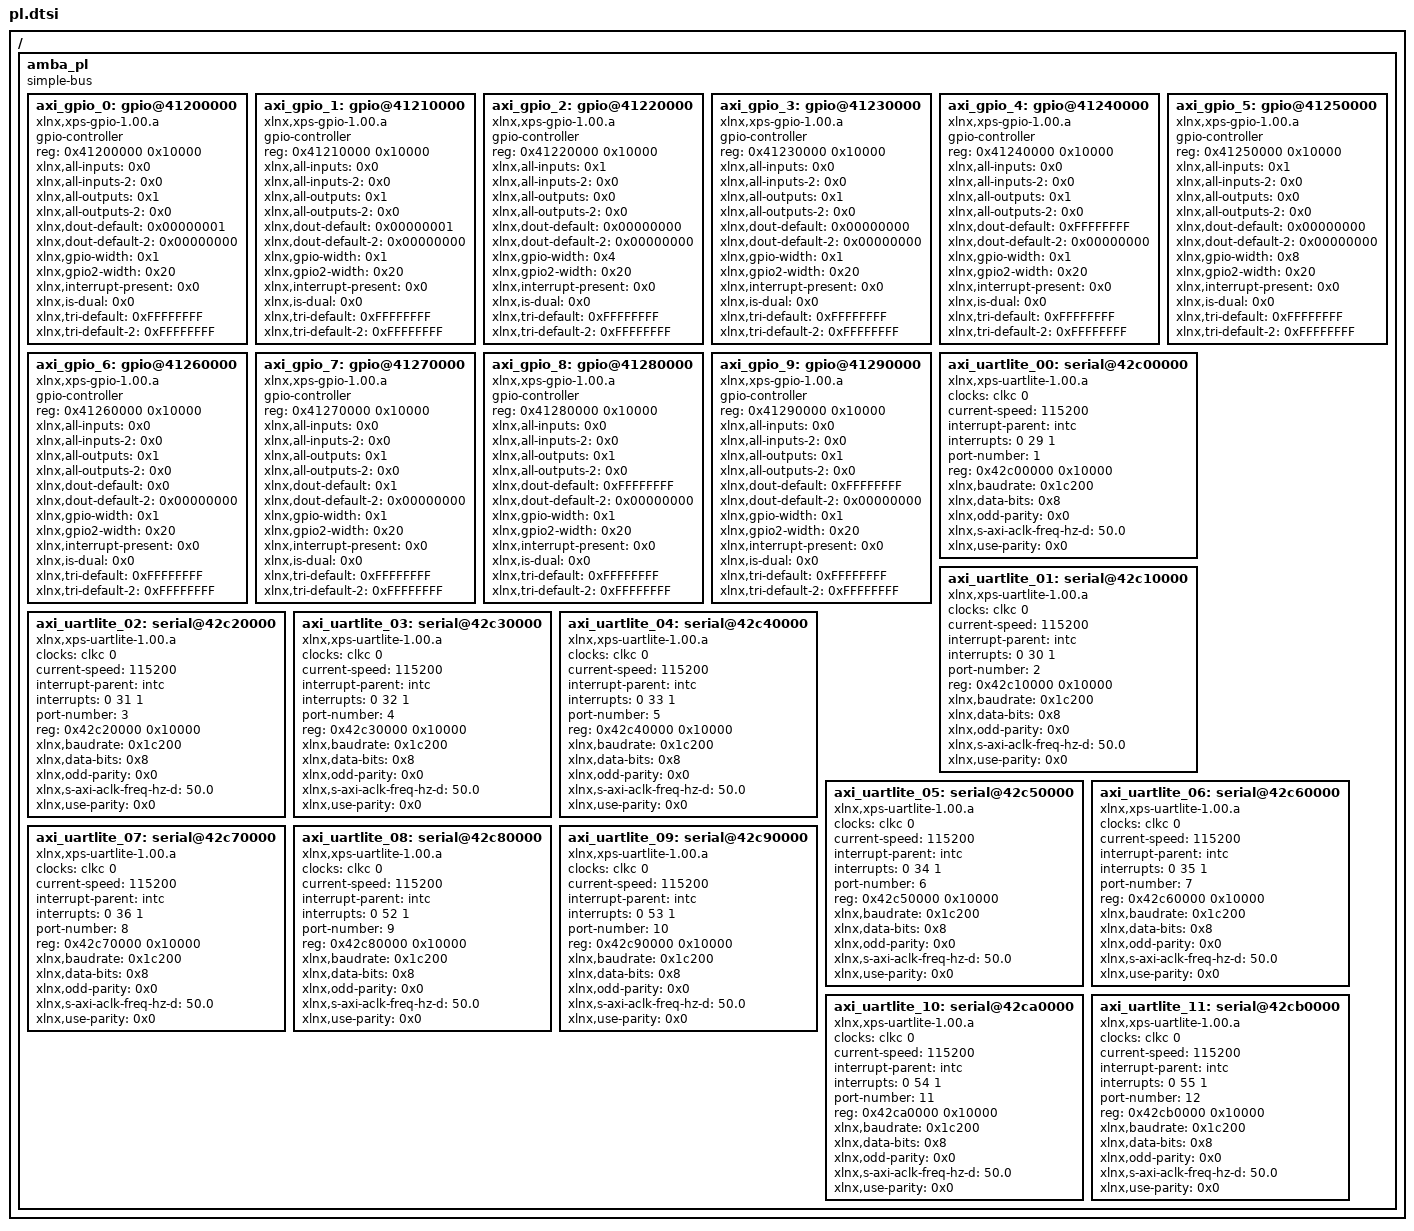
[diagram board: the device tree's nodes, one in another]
/*
 * CAUTION: This file is automatically generated by Xilinx.
 * Version:
 * Today is: Wed Mar  7 12:10:14 2018
 */


/ {
  amba_pl: amba_pl {
    #address-cells = <1>;
    #size-cells = <1>;
    compatible = "simple-bus";
    ranges ;
    axi_gpio_0: gpio@41200000 { /* Rst_i2c_ctl */
      #gpio-cells = <2>;
      compatible = "xlnx,xps-gpio-1.00.a";
      gpio-controller ;
      reg = <0x41200000 0x10000>;
      xlnx,all-inputs = <0x0>;
      xlnx,all-inputs-2 = <0x0>;
      xlnx,all-outputs = <0x1>;
      xlnx,all-outputs-2 = <0x0>;
      xlnx,dout-default = <0x00000001>;
      xlnx,dout-default-2 = <0x00000000>;
      xlnx,gpio-width = <0x1>;
      xlnx,gpio2-width = <0x20>;
      xlnx,interrupt-present = <0x0>;
      xlnx,is-dual = <0x0>;
      xlnx,tri-default = <0xFFFFFFFF>;
      xlnx,tri-default-2 = <0xFFFFFFFF>;
    };
    axi_gpio_1: gpio@41210000 { /* Rst_i2c_dbl */
      #gpio-cells = <2>;
      compatible = "xlnx,xps-gpio-1.00.a";
      gpio-controller ;
      reg = <0x41210000 0x10000>;
      xlnx,all-inputs = <0x0>;
      xlnx,all-inputs-2 = <0x0>;
      xlnx,all-outputs = <0x1>;
      xlnx,all-outputs-2 = <0x0>;
      xlnx,dout-default = <0x00000001>;
      xlnx,dout-default-2 = <0x00000000>;
      xlnx,gpio-width = <0x1>;
      xlnx,gpio2-width = <0x20>;
      xlnx,interrupt-present = <0x0>;
      xlnx,is-dual = <0x0>;
      xlnx,tri-default = <0xFFFFFFFF>;
      xlnx,tri-default-2 = <0xFFFFFFFF>;
    };
    axi_gpio_2: gpio@41220000 { /* board_ID */
      #gpio-cells = <2>;
      compatible = "xlnx,xps-gpio-1.00.a";
      gpio-controller ;
      reg = <0x41220000 0x10000>;
      xlnx,all-inputs = <0x1>;
      xlnx,all-inputs-2 = <0x0>;
      xlnx,all-outputs = <0x0>;
      xlnx,all-outputs-2 = <0x0>;
      xlnx,dout-default = <0x00000000>;
      xlnx,dout-default-2 = <0x00000000>;
      xlnx,gpio-width = <0x4>;
      xlnx,gpio2-width = <0x20>;
      xlnx,interrupt-present = <0x0>;
      xlnx,is-dual = <0x0>;
      xlnx,tri-default = <0xFFFFFFFF>;
      xlnx,tri-default-2 = <0xFFFFFFFF>;
    };
    axi_gpio_3: gpio@41230000 { /* Board ID_WP */
      #gpio-cells = <2>;
      compatible = "xlnx,xps-gpio-1.00.a";
      gpio-controller ;
      reg = <0x41230000 0x10000>;
      xlnx,all-inputs = <0x0>;
      xlnx,all-inputs-2 = <0x0>;
      xlnx,all-outputs = <0x1>;
      xlnx,all-outputs-2 = <0x0>;
      xlnx,dout-default = <0x00000000>;
      xlnx,dout-default-2 = <0x00000000>;
      xlnx,gpio-width = <0x1>;
      xlnx,gpio2-width = <0x20>;
      xlnx,interrupt-present = <0x0>;
      xlnx,is-dual = <0x0>;
      xlnx,tri-default = <0xFFFFFFFF>;
      xlnx,tri-default-2 = <0xFFFFFFFF>;
    };
    axi_gpio_4: gpio@41240000 { /* PS_ON */
      #gpio-cells = <2>;
      compatible = "xlnx,xps-gpio-1.00.a";
      gpio-controller ;
      reg = <0x41240000 0x10000>;
      xlnx,all-inputs = <0x0>;
      xlnx,all-inputs-2 = <0x0>;
      xlnx,all-outputs = <0x1>;
      xlnx,all-outputs-2 = <0x0>;
      xlnx,dout-default = <0xFFFFFFFF>;
      xlnx,dout-default-2 = <0x00000000>;
      xlnx,gpio-width = <0x1>;
      xlnx,gpio2-width = <0x20>;
      xlnx,interrupt-present = <0x0>;
      xlnx,is-dual = <0x0>;
      xlnx,tri-default = <0xFFFFFFFF>;
      xlnx,tri-default-2 = <0xFFFFFFFF>;
    };
    axi_gpio_5: gpio@41250000 { /* CLRREG_INT */
      #gpio-cells = <2>;
      compatible = "xlnx,xps-gpio-1.00.a";
      gpio-controller ;
      reg = <0x41250000 0x10000>;
      xlnx,all-inputs = <0x1>;
      xlnx,all-inputs-2 = <0x0>;
      xlnx,all-outputs = <0x0>;
      xlnx,all-outputs-2 = <0x0>;
      xlnx,dout-default = <0x00000000>;
      xlnx,dout-default-2 = <0x00000000>;
      xlnx,gpio-width = <0x8>;
      xlnx,gpio2-width = <0x20>;
      xlnx,interrupt-present = <0x0>;
      xlnx,is-dual = <0x0>;
      xlnx,tri-default = <0xFFFFFFFF>;
      xlnx,tri-default-2 = <0xFFFFFFFF>;
    };
    axi_gpio_6: gpio@41260000 { /* EN_2V5 */
      #gpio-cells = <2>;
      compatible = "xlnx,xps-gpio-1.00.a";
      gpio-controller ;
      reg = <0x41260000 0x10000>;
      xlnx,all-inputs = <0x0>;
      xlnx,all-inputs-2 = <0x0>;
      xlnx,all-outputs = <0x1>;
      xlnx,all-outputs-2 = <0x0>;
      xlnx,dout-default = <0x0>;
      xlnx,dout-default-2 = <0x00000000>;
      xlnx,gpio-width = <0x1>;
      xlnx,gpio2-width = <0x20>;
      xlnx,interrupt-present = <0x0>;
      xlnx,is-dual = <0x0>;
      xlnx,tri-default = <0xFFFFFFFF>;
      xlnx,tri-default-2 = <0xFFFFFFFF>;
    };
    axi_gpio_7: gpio@41270000 { /* RESET_RETIMER */
      #gpio-cells = <2>;
      compatible = "xlnx,xps-gpio-1.00.a";
      gpio-controller ;
      reg = <0x41270000 0x10000>;
      xlnx,all-inputs = <0x0>;
      xlnx,all-inputs-2 = <0x0>;
      xlnx,all-outputs = <0x1>;
      xlnx,all-outputs-2 = <0x0>;
      xlnx,dout-default = <0x1>;
      xlnx,dout-default-2 = <0x00000000>;
      xlnx,gpio-width = <0x1>;
      xlnx,gpio2-width = <0x20>;
      xlnx,interrupt-present = <0x0>;
      xlnx,is-dual = <0x0>;
      xlnx,tri-default = <0xFFFFFFFF>;
      xlnx,tri-default-2 = <0xFFFFFFFF>;
    };
    axi_gpio_8: gpio@41280000 { /* Serial Loopback EN */
      #gpio-cells = <2>;
      compatible = "xlnx,xps-gpio-1.00.a";
      gpio-controller ;
      reg = <0x41280000 0x10000>;
      xlnx,all-inputs = <0x0>;
      xlnx,all-inputs-2 = <0x0>;
      xlnx,all-outputs = <0x1>;
      xlnx,all-outputs-2 = <0x0>;
      xlnx,dout-default = <0xFFFFFFFF>;
      xlnx,dout-default-2 = <0x00000000>;
      xlnx,gpio-width = <0x1>;
      xlnx,gpio2-width = <0x20>;
      xlnx,interrupt-present = <0x0>;
      xlnx,is-dual = <0x0>;
      xlnx,tri-default = <0xFFFFFFFF>;
      xlnx,tri-default-2 = <0xFFFFFFFF>;
    };
    axi_gpio_9: gpio@41290000 { /* TRST_TO_MEZZ */
      #gpio-cells = <2>;
      compatible = "xlnx,xps-gpio-1.00.a";
      gpio-controller ;
      reg = <0x41290000 0x10000>;
      xlnx,all-inputs = <0x0>;
      xlnx,all-inputs-2 = <0x0>;
      xlnx,all-outputs = <0x1>;
      xlnx,all-outputs-2 = <0x0>;
      xlnx,dout-default = <0xFFFFFFFF>;
      xlnx,dout-default-2 = <0x00000000>;
      xlnx,gpio-width = <0x1>;
      xlnx,gpio2-width = <0x20>;
      xlnx,interrupt-present = <0x0>;
      xlnx,is-dual = <0x0>;
      xlnx,tri-default = <0xFFFFFFFF>;
      xlnx,tri-default-2 = <0xFFFFFFFF>;
    };
    axi_uartlite_00: serial@42c00000 {
      clock-names = "ref_clk";
      clocks = "clkc 0";
      compatible = "xlnx,xps-uartlite-1.00.a";
      current-speed = <115200>;
      device_type = "serial";
      interrupt-parent = <&intc>;
      interrupts = <0 29 1>;
      port-number = <1>;
      reg = <0x42c00000 0x10000>;
      xlnx,baudrate = <0x1c200>;
      xlnx,data-bits = <0x8>;
      xlnx,odd-parity = <0x0>;
      xlnx,s-axi-aclk-freq-hz-d = "50.0";
      xlnx,use-parity = <0x0>;
    };
    axi_uartlite_01: serial@42c10000 {
      clock-names = "ref_clk";
      clocks = "clkc 0";
      compatible = "xlnx,xps-uartlite-1.00.a";
      current-speed = <115200>;
      device_type = "serial";
      interrupt-parent = <&intc>;
      interrupts = <0 30 1>;
      port-number = <2>;
      reg = <0x42c10000 0x10000>;
      xlnx,baudrate = <0x1c200>;
      xlnx,data-bits = <0x8>;
      xlnx,odd-parity = <0x0>;
      xlnx,s-axi-aclk-freq-hz-d = "50.0";
      xlnx,use-parity = <0x0>;
    };
    axi_uartlite_02: serial@42c20000 {
      clock-names = "ref_clk";
      clocks = "clkc 0";
      compatible = "xlnx,xps-uartlite-1.00.a";
      current-speed = <115200>;
      device_type = "serial";
      interrupt-parent = <&intc>;
      interrupts = <0 31 1>;
      port-number = <3>;
      reg = <0x42c20000 0x10000>;
      xlnx,baudrate = <0x1c200>;
      xlnx,data-bits = <0x8>;
      xlnx,odd-parity = <0x0>;
      xlnx,s-axi-aclk-freq-hz-d = "50.0";
      xlnx,use-parity = <0x0>;
    };
    axi_uartlite_03: serial@42c30000 {
      clock-names = "ref_clk";
      clocks = "clkc 0";
      compatible = "xlnx,xps-uartlite-1.00.a";
      current-speed = <115200>;
      device_type = "serial";
      interrupt-parent = <&intc>;
      interrupts = <0 32 1>;
      port-number = <4>;
      reg = <0x42c30000 0x10000>;
      xlnx,baudrate = <0x1c200>;
      xlnx,data-bits = <0x8>;
      xlnx,odd-parity = <0x0>;
      xlnx,s-axi-aclk-freq-hz-d = "50.0";
      xlnx,use-parity = <0x0>;
    };
    axi_uartlite_04: serial@42c40000 {
      clock-names = "ref_clk";
      clocks = "clkc 0";
      compatible = "xlnx,xps-uartlite-1.00.a";
      current-speed = <115200>;
      device_type = "serial";
      interrupt-parent = <&intc>;
      interrupts = <0 33 1>;
      port-number = <5>;
      reg = <0x42c40000 0x10000>;
      xlnx,baudrate = <0x1c200>;
      xlnx,data-bits = <0x8>;
      xlnx,odd-parity = <0x0>;
      xlnx,s-axi-aclk-freq-hz-d = "50.0";
      xlnx,use-parity = <0x0>;
    };
    axi_uartlite_05: serial@42c50000 {
      clock-names = "ref_clk";
      clocks = "clkc 0";
      compatible = "xlnx,xps-uartlite-1.00.a";
      current-speed = <115200>;
      device_type = "serial";
      interrupt-parent = <&intc>;
      interrupts = <0 34 1>;
      port-number = <6>;
      reg = <0x42c50000 0x10000>;
      xlnx,baudrate = <0x1c200>;
      xlnx,data-bits = <0x8>;
      xlnx,odd-parity = <0x0>;
      xlnx,s-axi-aclk-freq-hz-d = "50.0";
      xlnx,use-parity = <0x0>;
    };
    axi_uartlite_06: serial@42c60000 {
      clock-names = "ref_clk";
      clocks = "clkc 0";
      compatible = "xlnx,xps-uartlite-1.00.a";
      current-speed = <115200>;
      device_type = "serial";
      interrupt-parent = <&intc>;
      interrupts = <0 35 1>;
      port-number = <7>;
      reg = <0x42c60000 0x10000>;
      xlnx,baudrate = <0x1c200>;
      xlnx,data-bits = <0x8>;
      xlnx,odd-parity = <0x0>;
      xlnx,s-axi-aclk-freq-hz-d = "50.0";
      xlnx,use-parity = <0x0>;
    };
    axi_uartlite_07: serial@42c70000 {
      clock-names = "ref_clk";
      clocks = "clkc 0";
      compatible = "xlnx,xps-uartlite-1.00.a";
      current-speed = <115200>;
      device_type = "serial";
      interrupt-parent = <&intc>;
      interrupts = <0 36 1>;
      port-number = <8>;
      reg = <0x42c70000 0x10000>;
      xlnx,baudrate = <0x1c200>;
      xlnx,data-bits = <0x8>;
      xlnx,odd-parity = <0x0>;
      xlnx,s-axi-aclk-freq-hz-d = "50.0";
      xlnx,use-parity = <0x0>;
    };
    axi_uartlite_08: serial@42c80000 {
      clock-names = "ref_clk";
      clocks = "clkc 0";
      compatible = "xlnx,xps-uartlite-1.00.a";
      current-speed = <115200>;
      device_type = "serial";
      interrupt-parent = <&intc>;
      interrupts = <0 52 1>;
      port-number = <9>;
      reg = <0x42c80000 0x10000>;
      xlnx,baudrate = <0x1c200>;
      xlnx,data-bits = <0x8>;
      xlnx,odd-parity = <0x0>;
      xlnx,s-axi-aclk-freq-hz-d = "50.0";
      xlnx,use-parity = <0x0>;
    };
    axi_uartlite_09: serial@42c90000 {
      clock-names = "ref_clk";
      clocks = "clkc 0";
      compatible = "xlnx,xps-uartlite-1.00.a";
      current-speed = <115200>;
      device_type = "serial";
      interrupt-parent = <&intc>;
      interrupts = <0 53 1>;
      port-number = <10>;
      reg = <0x42c90000 0x10000>;
      xlnx,baudrate = <0x1c200>;
      xlnx,data-bits = <0x8>;
      xlnx,odd-parity = <0x0>;
      xlnx,s-axi-aclk-freq-hz-d = "50.0";
      xlnx,use-parity = <0x0>;
    };
    axi_uartlite_10: serial@42ca0000 {
      clock-names = "ref_clk";
      clocks = "clkc 0";
      compatible = "xlnx,xps-uartlite-1.00.a";
      current-speed = <115200>;
      device_type = "serial";
      interrupt-parent = <&intc>;
      interrupts = <0 54 1>;
      port-number = <11>;
      reg = <0x42ca0000 0x10000>;
      xlnx,baudrate = <0x1c200>;
      xlnx,data-bits = <0x8>;
      xlnx,odd-parity = <0x0>;
      xlnx,s-axi-aclk-freq-hz-d = "50.0";
      xlnx,use-parity = <0x0>;
    };
    axi_uartlite_11: serial@42cb0000 {
      clock-names = "ref_clk";
      clocks = "clkc 0";
      compatible = "xlnx,xps-uartlite-1.00.a";
      current-speed = <115200>;
      device_type = "serial";
      interrupt-parent = <&intc>;
      interrupts = <0 55 1>;
      port-number = <12>;
      reg = <0x42cb0000 0x10000>;
      xlnx,baudrate = <0x1c200>;
      xlnx,data-bits = <0x8>;
      xlnx,odd-parity = <0x0>;
      xlnx,s-axi-aclk-freq-hz-d = "50.0";
      xlnx,use-parity = <0x0>;
    };
  };
};
